# M46B register map
File version: 2.0.2.1
Registers are 32-bit, read-write, reset 0x0 unless marked. A register's access mark holds for its fields unless they carry their own. Offsets are from the block's base; [hi:lo] are bit positions; {n}, {i} and the like mark numbered series.

## PB — Port B
Base 0x400C0100
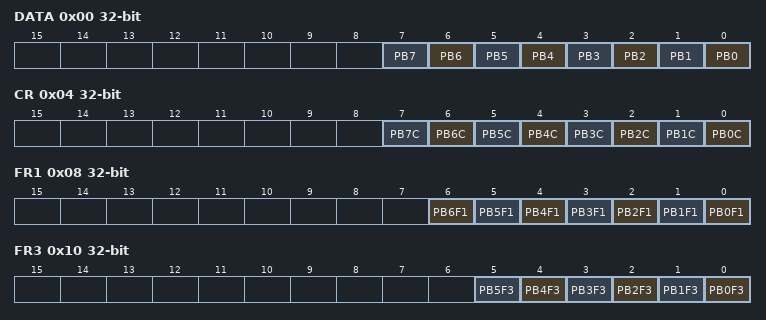
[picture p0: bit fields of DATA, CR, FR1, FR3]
0x00 DATA — Port B Data Register
  [n] PB{n} (n=0..7)
0x04 CR — Port B Output Control Register
  [n] PB{n}C (n=0..7)
0x08 FR1 — Port B Function Register 1
  [n] PB{n}F1 (n=0..6)
0x0C FR2 — Port B Function Register 2
  [6] PB6F2
0x10 FR3 — Port B Function Register 3
  [n] PB{n}F3 (n=0..5)
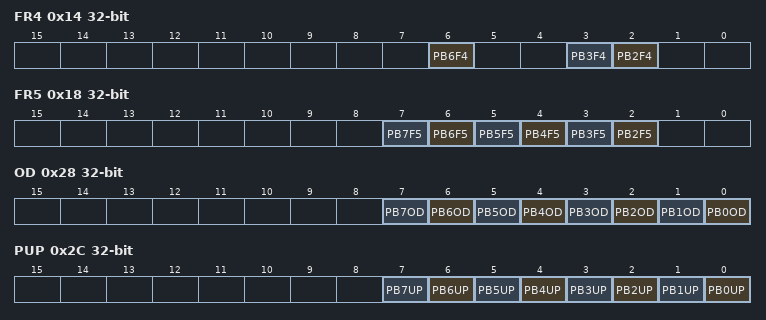
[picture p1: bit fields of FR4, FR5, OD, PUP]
0x14 FR4 — Port B Function Register 4
  [6] PB6F4, [3] PB3F4, [2] PB2F4
0x18 FR5 — Port B Function Register 5
  [n] PB{n}F5 (n=2..7)
0x28 OD — Port B Open Drain Control Register
  [n] PB{n}OD (n=0..7)
0x2C PUP — Port B Pull-up Control Register
  [n] PB{n}UP (n=0..7)
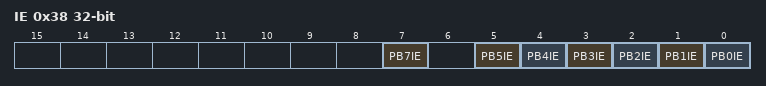
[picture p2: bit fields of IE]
0x38 IE — Port B Input Control Register
  [7] PB7IE, [n] PB{n}IE (n=0..5)

## PC — Port C
Base 0x400C0200
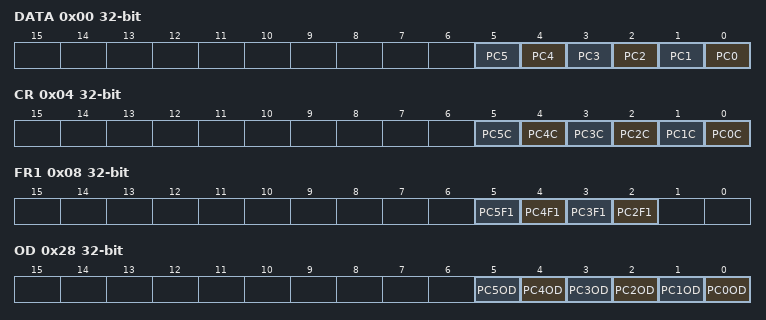
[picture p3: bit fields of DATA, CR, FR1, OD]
0x00 DATA — Port C Data Register
  [n] PC{n} (n=0..5)
0x04 CR — Port C Output Control Register
  [n] PC{n}C (n=0..5)
0x08 FR1 — Port C Function Register 1
  [n] PC{n}F1 (n=2..5)
0x0C FR2 — Port C Function Register 2
  [5] PC5F2
0x28 OD — Port C Open Drain Control Register
  [n] PC{n}OD (n=0..5)
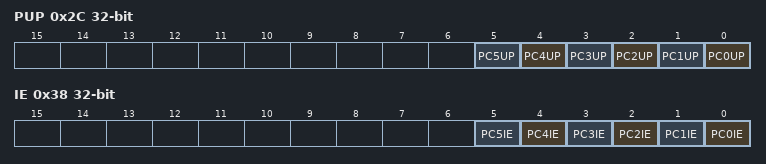
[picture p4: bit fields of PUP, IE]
0x2C PUP — Port C Pull-up Control Register
  [n] PC{n}UP (n=0..5)
0x38 IE — Port C Input Control Register
  [n] PC{n}IE (n=0..5)

## PD — Port D
Base 0x400C0300
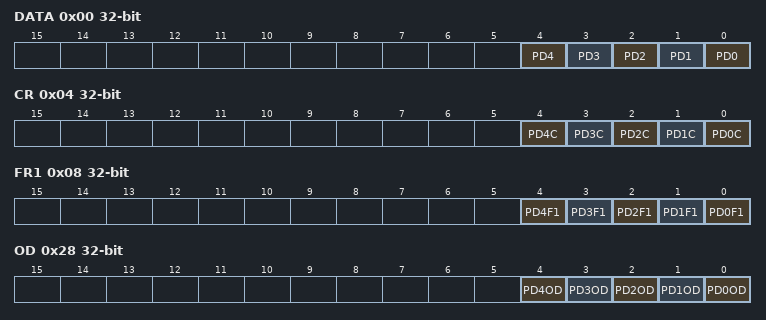
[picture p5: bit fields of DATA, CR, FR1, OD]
0x00 DATA — Port D Data Register
  [n] PD{n} (n=0..4)
0x04 CR — Port D Output Control Register
  [n] PD{n}C (n=0..4)
0x08 FR1 — Port D Function Register 1
  [n] PD{n}F1 (n=0..4)
0x28 OD — Port D Open Drain Control Register
  [n] PD{n}OD (n=0..4)
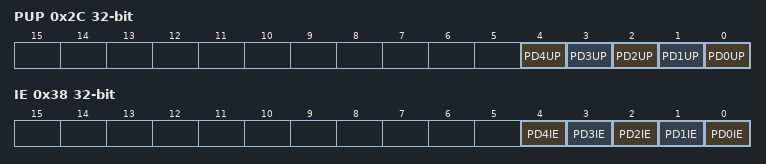
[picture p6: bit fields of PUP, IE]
0x2C PUP — Port D Pull-up Control Register
  [n] PD{n}UP (n=0..4)
0x38 IE — Port D Input Control Register
  [n] PD{n}IE (n=0..4)

## PE — Port E
Base 0x400C0400
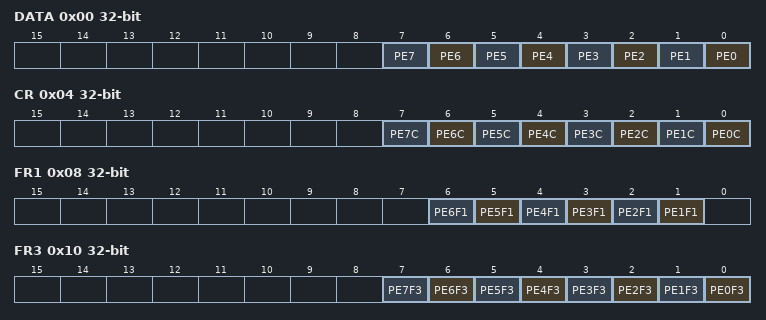
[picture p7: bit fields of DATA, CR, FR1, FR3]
0x00 DATA — Port E Data Register
  [n] PE{n} (n=0..7)
0x04 CR — Port E Output Control Register
  [n] PE{n}C (n=0..7)
0x08 FR1 — Port E Function Register 1
  [n] PE{n}F1 (n=1..6)
0x10 FR3 — Port E Function Register 3
  [n] PE{n}F3 (n=0..7)
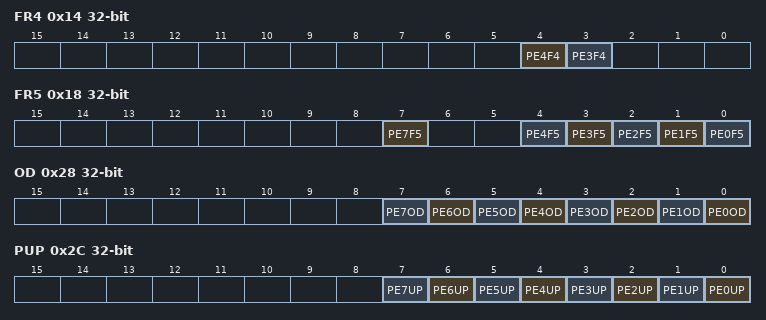
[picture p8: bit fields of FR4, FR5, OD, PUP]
0x14 FR4 — Port E Function Register 4
  [4] PE4F4, [3] PE3F4
0x18 FR5 — Port E Function Register 5
  [7] PE7F5, [n] PE{n}F5 (n=0..4)
0x28 OD — Port E Open Drain Control Register
  [n] PE{n}OD (n=0..7)
0x2C PUP — Port E Pull-up Control Register
  [n] PE{n}UP (n=0..7)
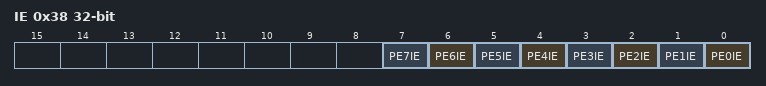
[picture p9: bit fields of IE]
0x38 IE — Port E Input Control Register
  [n] PE{n}IE (n=0..7)

## PF — Port F
Base 0x400C0500
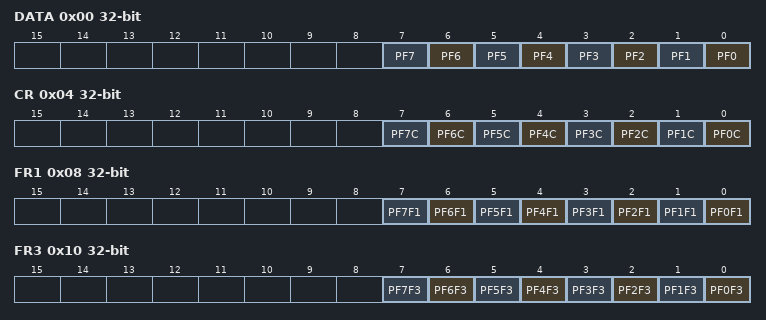
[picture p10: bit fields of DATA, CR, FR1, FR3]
0x00 DATA — Port F Data Register
  [n] PF{n} (n=0..7)
0x04 CR — Port F Output Control Register
  [n] PF{n}C (n=0..7)
0x08 FR1 — Port F Function Register 1
  [n] PF{n}F1 (n=0..7)
0x10 FR3 — Port F Function Register 3
  [n] PF{n}F3 (n=0..7)
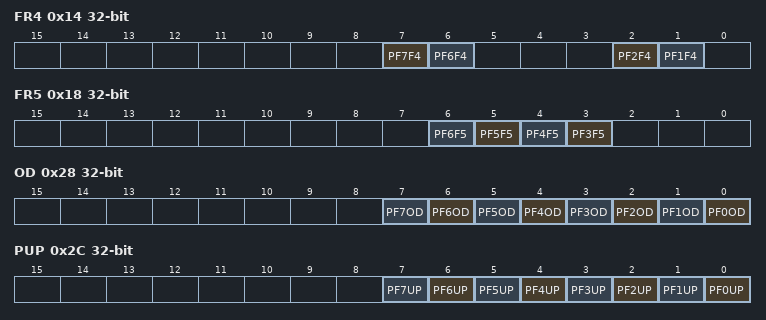
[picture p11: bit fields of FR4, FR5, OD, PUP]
0x14 FR4 — Port F Function Register 4
  [7] PF7F4, [6] PF6F4, [2] PF2F4, [1] PF1F4
0x18 FR5 — Port F Function Register 5
  [n] PF{n}F5 (n=3..6)
0x28 OD — Port F Open Drain Control Register
  [n] PF{n}OD (n=0..7)
0x2C PUP — Port E Pull-up Control Register
  [n] PF{n}UP (n=0..7)
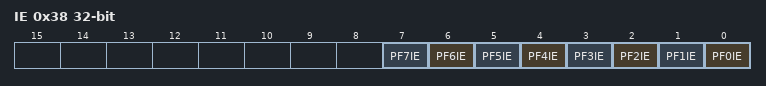
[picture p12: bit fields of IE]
0x38 IE — Port F Input Control Register
  [n] PF{n}IE (n=0..7)

## PG — Port G
Base 0x400C0600
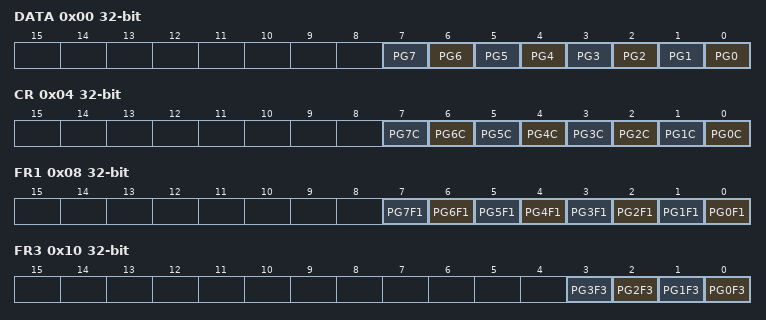
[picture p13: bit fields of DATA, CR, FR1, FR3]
0x00 DATA — Port G Data Register
  [n] PG{n} (n=0..7)
0x04 CR — Port G Output Control Register
  [n] PG{n}C (n=0..7)
0x08 FR1 — Port G Function Register 1
  [n] PG{n}F1 (n=0..7)
0x10 FR3 — Port G Function Register 3
  [n] PG{n}F3 (n=0..3)
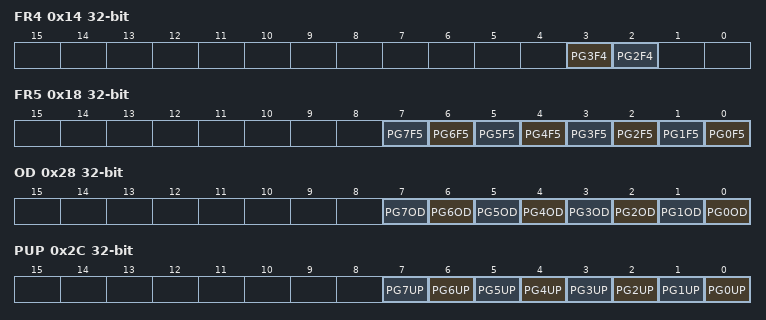
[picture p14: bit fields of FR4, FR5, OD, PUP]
0x14 FR4 — Port G Function Register 4
  [3] PG3F4, [2] PG2F4
0x18 FR5 — Port G Function Register 5
  [n] PG{n}F5 (n=0..7)
0x28 OD — Port G Open Drain Control Register
  [n] PG{n}OD (n=0..7)
0x2C PUP — Port G Pull-up Control Register
  [n] PG{n}UP (n=0..7)
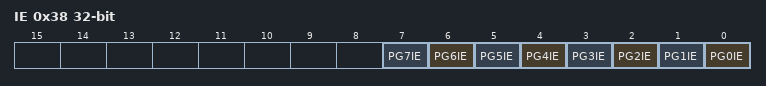
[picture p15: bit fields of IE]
0x38 IE — Port G Input Control Register
  [n] PG{n}IE (n=0..7)

## PH — Port H
Base 0x400C0700
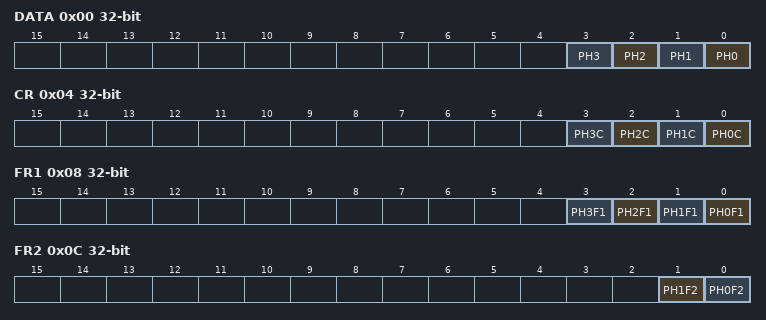
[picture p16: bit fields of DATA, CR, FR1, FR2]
0x00 DATA — Port H Data Register
  [n] PH{n} (n=0..3)
0x04 CR — Port H Output Control Register
  [n] PH{n}C (n=0..3)
0x08 FR1 — Port H Function Register 1
  [n] PH{n}F1 (n=0..3)
0x0C FR2 — Port H Function Register 2
  [1] PH1F2, [0] PH0F2
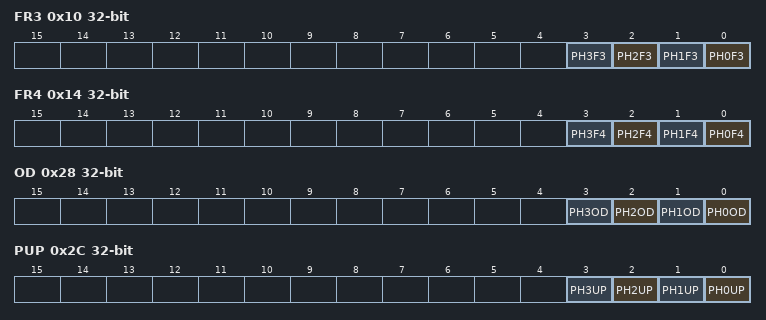
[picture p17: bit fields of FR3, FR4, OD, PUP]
0x10 FR3 — Port H Function Register 3
  [n] PH{n}F3 (n=0..3)
0x14 FR4 — Port H Function Register 4
  [n] PH{n}F4 (n=0..3)
0x28 OD — Port H Open Drain Control Register
  [n] PH{n}OD (n=0..3)
0x2C PUP — Port H Pull-up Control Register
  [n] PH{n}UP (n=0..3)
0x38 IE — Port H Input Control Register
  [n] PH{n}IE (n=0..3)
